# ATmega8515 register map
Vendor: Atmel; File version: 1.0
CPU: other r0p0, little endian, no MPU, no FPU, 4 interrupt priority bits
Registers are 8-bit, read-write, reset 0x0 unless marked. A register's access mark holds for its fields unless they carry their own. Offsets are from the block's base; [hi:lo] are bit positions.

## EEPROM
Base 0x0000003C
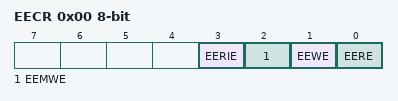
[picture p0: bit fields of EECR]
0x00 EECR — EEPROM Control Register
  [3] EERIE — EEPROM Ready Interrupt Enable
  [2] EEMWE — EEPROM Master Write Enable
  [1] EEWE — EEPROM Write Enable
  [0] EERE — EEPROM Read Enable
0x01 EEDR — EEPROM Data Register
0x02 EEAR 16-bit (reset mask 0xFF) — EEPROM Address Register Bytes

## EXINT — External Interrupts
Base 0x0000005A
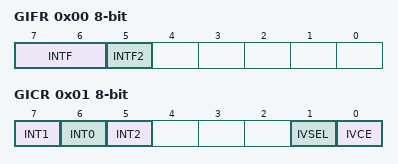
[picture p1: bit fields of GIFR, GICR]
0x00 GIFR — General Interrupt Flag Register
  [7:6] INTF — External Interrupt Flags
  [5] INTF2 — External Interrupt Flag 2
0x01 GICR — General Interrupt Control Register
  [7] INT1 — External Interrupt Request 1 Enable
  [6] INT0 — External Interrupt Request 0 Enable
  [5] INT2 — External Interrupt Request 2 Enable
  [1] IVSEL — Interrupt Vector Select
  [0] IVCE — Interrupt Vector Change Enable

## LOCKBIT — Lockbits
Base 0x00000000
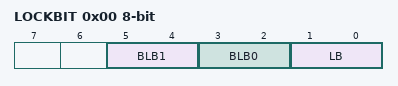
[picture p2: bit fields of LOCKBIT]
0x00 LOCKBIT
  [5:4] BLB1 — Boot Loader Protection Mode
    0=LPM_SPM_DISABLE (LPM and SPM prohibited in Boot Section); 1=LPM_DISABLE (LPM prohibited in Boot Section); 2=SPM_DISABLE (SPM prohibited in Boot Section); 3=NO_LOCK (No lock on SPM and LPM in Boot Section)
  [3:2] BLB0 — Boot Loader Protection Mode
    0=LPM_SPM_DISABLE (LPM and SPM prohibited in Application Section); 1=LPM_DISABLE (LPM prohibited in Application Section); 2=SPM_DISABLE (SPM prohibited in Application Section); 3=NO_LOCK (No lock on SPM and LPM in Application Section)
  [1:0] LB — Memory Lock
    0=PROG_VER_DISABLED (Further programming and verification disabled); 2=PROG_DISABLED (Further programming disabled); 3=NO_LOCK (No memory lock features enabled)

## PORTA — I/O Port
Base 0x00000039
0x00 PINA — Port A Input Pins
0x01 DDRA — Port A Data Direction Register
0x02 PORTA — Port A Data Register

## PORTB — I/O Port
Base 0x00000036
0x00 PINB — Port B Input Pins
0x01 DDRB — Port B Data Direction Register
0x02 PORTB — Port B Data Register

## PORTC — I/O Port
Base 0x00000033
0x00 PINC — Port C Input Pins
0x01 DDRC — Port C Data Direction Register
0x02 PORTC — Port C Data Register

## PORTD — I/O Port
Base 0x00000030
0x00 PIND — Port D Input Pins
0x01 DDRD — Port D Data Direction Register
0x02 PORTD — Port D Data Register

## PORTE — I/O Port
Base 0x00000025
0x00 PINE — Port E Input Pins
0x01 DDRE — Port E Data Direction Register
0x02 PORTE — Port E Data Register

## SPI — Serial Peripheral Interface
Base 0x0000002D
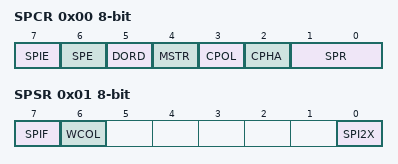
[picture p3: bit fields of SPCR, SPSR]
0x00 SPCR — SPI Control Register
  [7] SPIE — SPI Interrupt Enable
  [6] SPE — SPI Enable
  [5] DORD — Data Order
  [4] MSTR — Master/Slave Select
  [3] CPOL — Clock polarity
  [2] CPHA — Clock Phase
  [1:0] SPR — SPI Clock Rate Selects
    0=fosc/4; 1=fosc/16; 2=fosc/64; 3=fosc/128
0x01 SPSR — SPI Status Register
  [7] SPIF — SPI Interrupt Flag
  [6] WCOL — Write Collision Flag
  [0] SPI2X — Double SPI Speed Bit
0x02 SPDR — SPI Data Register

## TC0 — Timer/Counter, 8-bit
Base 0x00000051
0x00 OCR0 — Timer/Counter 0 Output Compare Register
0x01 TCNT0 — Timer/Counter 0 Register
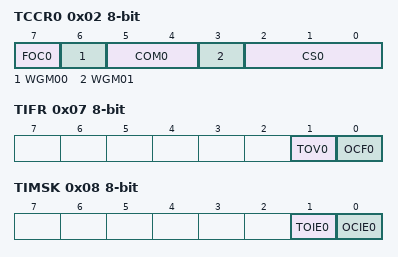
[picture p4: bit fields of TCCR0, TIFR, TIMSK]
0x02 TCCR0 — Timer/Counter 0 Control Register
  [7] FOC0 — Force Output Compare
  [6] WGM00 — Waveform Generation Mode 0
    0=Normal; 1=CTC
  [5:4] COM0 — Compare Match Output Modes
  [3] WGM01 — Waveform Generation Mode 1
  [2:0] CS0 — Clock Selects
    0=No Clock Source (Stopped); 1=Running, No Prescaling; 2=Running, CLK/8; 3=Running, CLK/64; 4=Running, CLK/256; 5=Running, CLK/1024; 6=Running, ExtClk Tx Falling Edge; 7=Running, ExtClk Tx Rising Edge
0x07 TIFR — Timer/Counter Interrupt Flag register
  [1] TOV0 — Timer/Counter0 Overflow Flag
  [0] OCF0 — Output Compare Flag 0
0x08 TIMSK — Timer/Counter Interrupt Mask Register
  [1] TOIE0 — Timer/Counter0 Overflow Interrupt Enable
  [0] OCIE0 — Timer/Counter0 Output Compare Match Interrupt register

## TC1 — Timer/Counter, 16-bit
Base 0x00000044
0x00 ICR1 16-bit (reset mask 0xFF) — Timer/Counter1 Input Capture Register Bytes
0x04 OCR1B 16-bit (reset mask 0xFF) — Timer/Counter1 Output Compare Register B Bytes
0x06 OCR1A 16-bit (reset mask 0xFF) — Timer/Counter1 Output Compare Register A Bytes
0x08 TCNT1 16-bit (reset mask 0xFF) — Timer/Counter1 Bytes
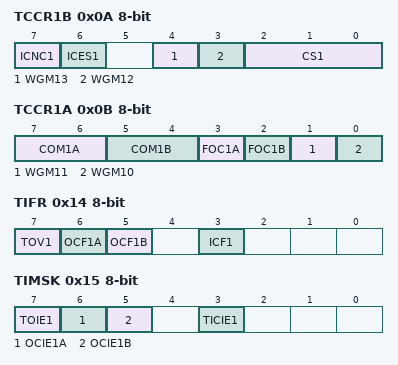
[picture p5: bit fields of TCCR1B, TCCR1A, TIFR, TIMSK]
0x0A TCCR1B — Timer/Counter1 Control Register B
  [7] ICNC1 — Input Capture 1 Noise Canceler
  [6] ICES1 — Input Capture 1 Edge Select
  [4] WGM13 — Waveform Generation Mode
  [3] WGM12 — Waveform Generation Mode
  [2:0] CS1 — Clock Select1 bits
    0=No Clock Source (Stopped); 1=Running, No Prescaling; 2=Running, CLK/8; 3=Running, CLK/64; 4=Running, CLK/256; 5=Running, CLK/1024; 6=Running, ExtClk Tx Falling Edge; 7=Running, ExtClk Tx Rising Edge
0x0B TCCR1A — Timer/Counter1 Control Register A
  [7:6] COM1A — Compare Output Mode 1A, bits
  [5:4] COM1B — Compare Output Mode 1B, bits
  [3] FOC1A — Force Output Compare for Channel A
  [2] FOC1B — Force Output Compare for Channel B
  [1] WGM11 — Waveform Generation Mode
  [0] WGM10 — Waveform Generation Mode
0x14 TIFR — Timer/Counter Interrupt Flag register
  [7] TOV1 — Timer/Counter1 Overflow Flag
  [6] OCF1A — Output Compare Flag 1A
  [5] OCF1B — Output Compare Flag 1B
  [3] ICF1 — Input Capture Flag 1
0x15 TIMSK — Timer/Counter Interrupt Mask Register
  [7] TOIE1 — Timer/Counter1 Overflow Interrupt Enable
  [6] OCIE1A — Timer/Counter1 Output CompareA Match Interrupt Enable
  [5] OCIE1B — Timer/Counter1 Output CompareB Match Interrupt Enable
  [3] TICIE1 — Timer/Counter1 Input Capture Interrupt Enable

## USART
Base 0x00000029
0x00 UBRRL — USART Baud Rate Register Low Byte
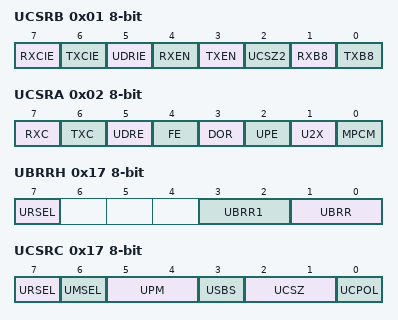
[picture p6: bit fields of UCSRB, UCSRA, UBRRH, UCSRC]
0x01 UCSRB — USART Control and Status Register B
  [7] RXCIE — RX Complete Interrupt Enable
  [6] TXCIE — TX Complete Interrupt Enable
  [5] UDRIE — USART Data register Empty Interrupt Enable
  [4] RXEN — Receiver Enable
  [3] TXEN — Transmitter Enable
  [2] UCSZ2 — Character Size Bit 2
  [1] RXB8 — Receive Data Bit 8
  [0] TXB8 — Transmit Data Bit 8
0x02 UCSRA — USART Control and Status Register A
  [7] RXC — USART Receive Complete
  [6] TXC — USART Transmitt Complete
  [5] UDRE — USART Data Register Empty
  [4] FE — Framing Error
  [3] DOR — Data overRun
  [2] UPE — Parity Error
  [1] U2X — Double the USART transmission speed
  [0] MPCM — Multi-processor Communication Mode
0x03 UDR — USART I/O Data Register
0x17 UBRRH — USART Baud Rate Register High Byte
  [7] URSEL — Register Select
  [3:2] UBRR1 — USART Baud Rate Register bit 11
  [1:0] UBRR — USART Baud Rate Register bits
0x17 UCSRC — USART Control and Status Register C
  [7] URSEL — Register Select
  [6] UMSEL — USART Mode Select
    0=Asynchronous Operation; 1=Synchronous Operation
  [5:4] UPM — Parity Mode Bits
    0=Disabled; 2=Enabled, Even Parity; 3=Enabled, Odd Parity
  [3] USBS — Stop Bit Select
    0=1-bit; 1=2-bit
  [2:1] UCSZ — Character Size Bits
  [0] UCPOL — Clock Polarity

## WDT — Watchdog Timer
Base 0x00000041
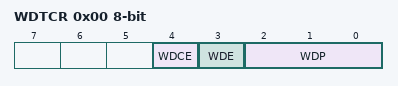
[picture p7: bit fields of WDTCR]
0x00 WDTCR — Watchdog Timer Control Register
  [4] WDCE — Watchdog Change Enable
  [3] WDE — Watch Dog Enable
  [2:0] WDP — Watch Dog Timer Prescaler bits
    0=Oscillator Cycles 16K; 1=Oscillator Cycles 32K; 2=Oscillator Cycles 64K; 3=Oscillator Cycles 128K; 4=Oscillator Cycles 256K; 5=Oscillator Cycles 512K; 6=Oscillator Cycles 1024K; 7=Oscillator Cycles 2048K
